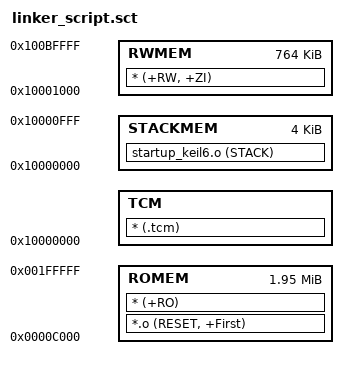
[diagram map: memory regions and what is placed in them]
;******************************************************************************
;
; Scatter file for Keil linker configuration.
;
;******************************************************************************
LR_1 0x0000C000
{
    ROMEM 0x0000C000 0x001F4000
    {
        *.o (RESET, +First)
        * (+RO)
    }

    RWMEM 0x10001000 0x000BF000
    {
        * (+RW, +ZI)
    }

    TCM 0x10000000 0x00000000
    {
        * (.tcm)
    }

    STACKMEM 0x10000000 0x00001000
    {
        startup_keil6.o (STACK)
    }
}
